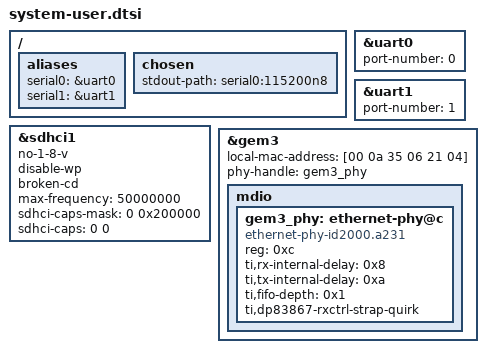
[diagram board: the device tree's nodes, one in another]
// SPDX-License-Identifier: MIT
// Copyright (C) 2025-2026, Opsero Electronic Design Inc.  All rights reserved.

/*
 * SoC-side board fixups for the ZCU104, layered on top of the
 * gen-machineconf / lopper-generated cortexa53-linux.dts (which already
 * carries the PS config and the PL xilinx_xdma PCIe node from the XSA).
 *
 * UART (ttyPS console):
 *   The 2025.2 lopper/gen-machineconf flow emits port-number = <0> on BOTH
 *   uart0 (ff000000) and uart1 (ff010000), so the ttyPS0/ttyPS1 assignment is
 *   left to probe order. This board's console is on psu_uart_0, so pin the
 *   port numbers (and serial aliases) explicitly. Mirrors the PetaLinux BSPs.
 *
 * SD card (sdhci1 / ff170000.mmc):
 *   The Vivado design configures the SD interface as "custom"
 *   (xlnx,sd-board-interface = "custom"), so the XSA-derived SDT exports a
 *   minimal sdhci1 node with a zero 200 MHz output tap delay. Linux then
 *   negotiates UHS-I SDR104 and immediately fails reading the partition
 *   table ("mmcblk0: recovery failed!" / sector-0 I/O error -> root-fs
 *   mount panic). The ZCU104's SD level shifter cannot sustain the faster
 *   UHS modes, so cap the controller at high-speed (<=50 MHz, no 1.8 V
 *   switch). These values mirror the PetaLinux zcu104 BSP for this repo and
 *   the stock 2025.2 xilinx-zcu104 BSP, both proven on this hardware. PCIe
 *   NVMe (not the SD card) is the performance path, so this is harmless.
 */

&uart0 {
   port-number = <0>;
};

&uart1 {
   port-number = <1>;
};

/ {
   aliases {
      serial0 = &uart0;
      serial1 = &uart1;
   };
   chosen {
      stdout-path = "serial0:115200n8";
   };
};

&sdhci1 {
   no-1-8-v;
   disable-wp;
   broken-cd;
   max-frequency = <50000000>;
   /* Mask the UHS capability bits the level shifter can't sustain. */
   sdhci-caps-mask = <0 0x200000>;
   sdhci-caps = <0 0>;
};

/* PS GEM3 (board RJ45): the SDT flow does not describe the board-level
 * TI DP83867 PHY, so Linux falls back to the Generic PHY driver and the
 * RGMII clock delays are never programmed - the link negotiates 1G but
 * passes no packets. Values from the official zynqmp-zcu104-revA/revC.dts
 * (PHY at MDIO address 0xc; its reset-gpios line is omitted because the
 * TCA6416 expander it references is not in the SDT device tree - the
 * PHY powers up out of reset from its straps). The fixed MAC replaces
 * the random one the SDT flow leaves us with, keeping DHCP leases
 * stable across boots.
 */
&gem3 {
	local-mac-address = [00 0a 35 06 21 04];
	phy-handle = <&gem3_phy>;
	mdio {
		#address-cells = <1>;
		#size-cells = <0>;
		gem3_phy: ethernet-phy@c {
			compatible = "ethernet-phy-id2000.a231";
			reg = <0xc>;
			ti,rx-internal-delay = <0x8>;
			ti,tx-internal-delay = <0xa>;
			ti,fifo-depth = <0x1>;
			ti,dp83867-rxctrl-strap-quirk;
		};
	};
};
